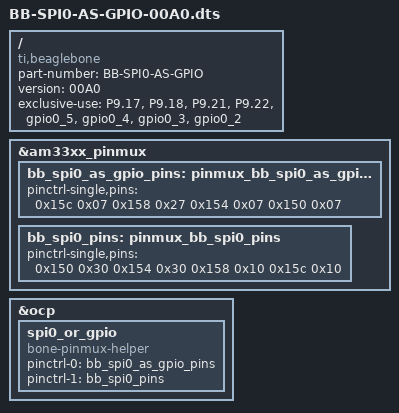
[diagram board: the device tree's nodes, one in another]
/*###############################################################*/
/* BB-SPI0-AS-GPIO-00A0.dts                                      */
/*###############################################################*/
/*
* Copyright (C) 2013 Pantelis Antoniou <panto@antoniou-consulting.com>
*
* This program is free software; you can redistribute it and/or modify
* it under the terms of the GNU General Public License version 2 as
* published by the Free Software Foundation.
*/
/dts-v1/;
/plugin/;

/ {
	compatible = "ti,beaglebone", "ti,beaglebone-black";

	/* identification */
	part-number = "BB-SPI0-AS-GPIO";
	version = "00A0";

	/* state the resources this cape uses */
	exclusive-use =
		/* the pin header uses */
		"P9.17",	/* gpio */
		"P9.18",	/* gpio */
		"P9.21",	/* gpio */
		"P9.22",	/* gpio */
		/* the hardware IP uses */
		"gpio0_5", "gpio0_4", "gpio0_3", "gpio0_2";

	fragment@0 {
		target = <&am33xx_pinmux>;
		__overlay__ {
			bb_spi0_as_gpio_pins: pinmux_bb_spi0_as_gpio_pins {
				pinctrl-single,pins = <
					0x15c 0x07 	/* P9 17 GPIO0_5:  spi0_cs0.gpio0_5 | MODE7 | OUTPUT */
					0x158 0x27	/* P9 18 GPIO0_4:  spi0_d1.gpio0_4 | MODE7 | INPUT */
					0x154 0x07 	/* P9 21 GPIO0_3:  spi0_d0.gpio0_3 | MODE7 | OUTPUT */
					0x150 0x07	/* P9 22 GPIO0_2:  spi0_sclk.gpio0_2 | MODE7 | OUTPUT */
				>;
			};
			bb_spi0_pins: pinmux_bb_spi0_pins {
				pinctrl-single,pins = <
					0x150 0x30	/* spi0_sclk.spi0_sclk, INPUT_PULLUP | MODE0 */
					0x154 0x30	/* spi0_d0.spi0_d0, INPUT_PULLUP | MODE0 */
					0x158 0x10	/* spi0_d1.spi0_d1, OUTPUT_PULLUP | MODE0 */
					0x15c 0x10	/* spi0_cs0.spi0_cs0, OUTPUT_PULLUP | MODE0 */
				>;
			};
		};	
	};
	fragment@2 {
		target = <&ocp>;
		__overlay__ {

			spi0_or_gpio {
				compatible = "bone-pinmux-helper";
				status = "okay";
				/*pinctrl-names = "default"; */
				pinctrl-names = "pluto_config", "pluto_spi";
				pinctrl-0 = <&bb_spi0_as_gpio_pins>;
				pinctrl-1 = <&bb_spi0_pins>;
			};
			
		};
	};
};
